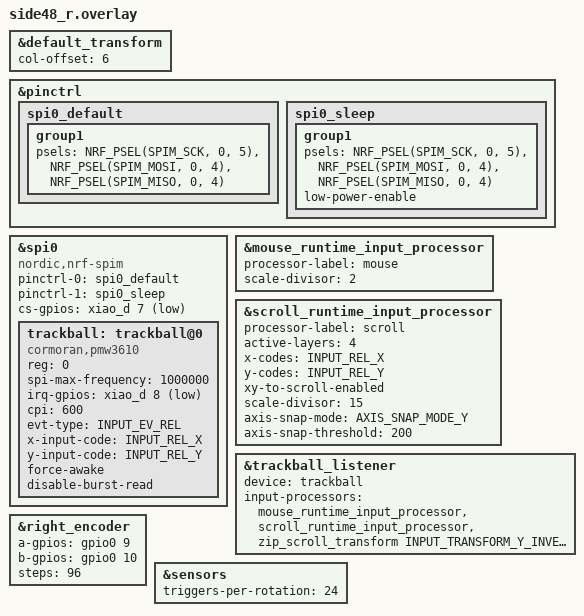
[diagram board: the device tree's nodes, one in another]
#include "side48.dtsi"
#include <input/processors.dtsi>
#include <input/processors/runtime-input-processor.dtsi>
#include <dt-bindings/zmk/runtime_input_processor.h>


&default_transform {
    col-offset = <6>;
};


//trackballの設定
&pinctrl {
    spi0_default: spi0_default {    //通常動作時
        group1 {
            psels = <NRF_PSEL(SPIM_SCK,  0, 5)>,    //P0.05(SCLK)
                    <NRF_PSEL(SPIM_MOSI, 0, 4)>,    //P0.04(SDIO(MOSI,MISO兼用))
                    <NRF_PSEL(SPIM_MISO, 0, 4)>;
        };
    };

    spi0_sleep: spi0_sleep {        //スリープ時
        group1 {
            psels = <NRF_PSEL(SPIM_SCK,  0, 5)>,
                    <NRF_PSEL(SPIM_MOSI, 0, 4)>,
                    <NRF_PSEL(SPIM_MISO, 0, 4)>;
            low-power-enable;
        };
    };
};

&spi0 {
    status = "okay";
    compatible = "nordic,nrf-spim";
    pinctrl-0 = <&spi0_default>;
    pinctrl-1 = <&spi0_sleep>;
    pinctrl-names = "default", "sleep";
    cs-gpios = <&xiao_d 7 GPIO_ACTIVE_LOW>;  //P1.12(CS)

    trackball: trackball@0 {
        status = "okay";
        compatible = "cormoran,pmw3610";
        reg = <0>;
        spi-max-frequency = <1000000>;
        irq-gpios = <&xiao_d 8 (GPIO_ACTIVE_LOW | GPIO_PULL_UP)>; //P1.13(MOTION)
        cpi = <600>;
        evt-type = <INPUT_EV_REL>;
        x-input-code = <INPUT_REL_X>;
        y-input-code = <INPUT_REL_Y>;
        force-awake;
        disable-burst-read;     //MOSI/MISOを1本の線で共用しているため、バーストリードは無効
    };
};

// DYA Studioからランタイムで調整できる入力プロセッサ
&mouse_runtime_input_processor {
    processor-label = "mouse";
    scale-divisor = <2>;                        //カーソル移動量を1/2倍(従来の zip_xy_scaler 1 2 相当)
};

&scroll_runtime_input_processor {
    processor-label = "scroll";
    active-layers = <4>;                        //レイヤー2(BIT(2))でスクロールモード
    x-codes = <INPUT_REL_X>;
    y-codes = <INPUT_REL_Y>;
    xy-to-scroll-enabled;                       //移動量をスクロールに変換
    scale-divisor = <15>;                       //スクロール量を1/15倍(従来設定)
    axis-snap-mode = <AXIS_SNAP_MODE_Y>;        //縦スクロールのみ(従来のX方向無効化に相当)
    axis-snap-threshold = <200>;
};

// Overrides for the input listener node
&trackball_listener {
    status = "okay";
    device = <&trackball>;
    input-processors =
            <&mouse_runtime_input_processor>,
            <&scroll_runtime_input_processor>,
            <&zip_scroll_transform INPUT_TRANSFORM_Y_INVERT>;   //スクロールのY方向を反転
};


//encoderの設定
&right_encoder{
    a-gpios = <&gpio0  9 (GPIO_ACTIVE_HIGH | GPIO_PULL_UP)>;
    b-gpios = <&gpio0 10 (GPIO_ACTIVE_HIGH | GPIO_PULL_UP)>;
    steps = <96>;
    status = "okay";
};

&sensors {
   triggers-per-rotation = <24>;
};

